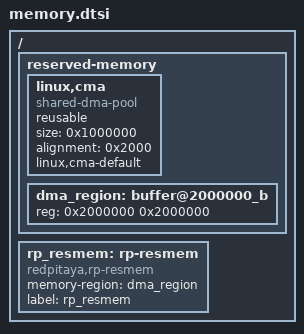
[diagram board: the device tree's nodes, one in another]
/*
 * define memory for DMA pool
 */

/ {
	reserved-memory {
		#address-cells = <1>;
		#size-cells = <1>;
		ranges;
		linux,cma {
			compatible = "shared-dma-pool";
			reusable;
			size = <0x1000000>;
			alignment = <0x2000>;
			linux,cma-default;
		};

		dma_region: buffer@2000000_b {
			reg = <0x2000000 0x2000000>;
		};

	};

	/* user-space access to dma_region (/dev/rp_resmem), drivers/redpitaya/rp_resmem.c */
	rp_resmem: rp-resmem {
		compatible = "redpitaya,rp-resmem";
		memory-region = <&dma_region>;
		label = "rp_resmem";
	};
};
